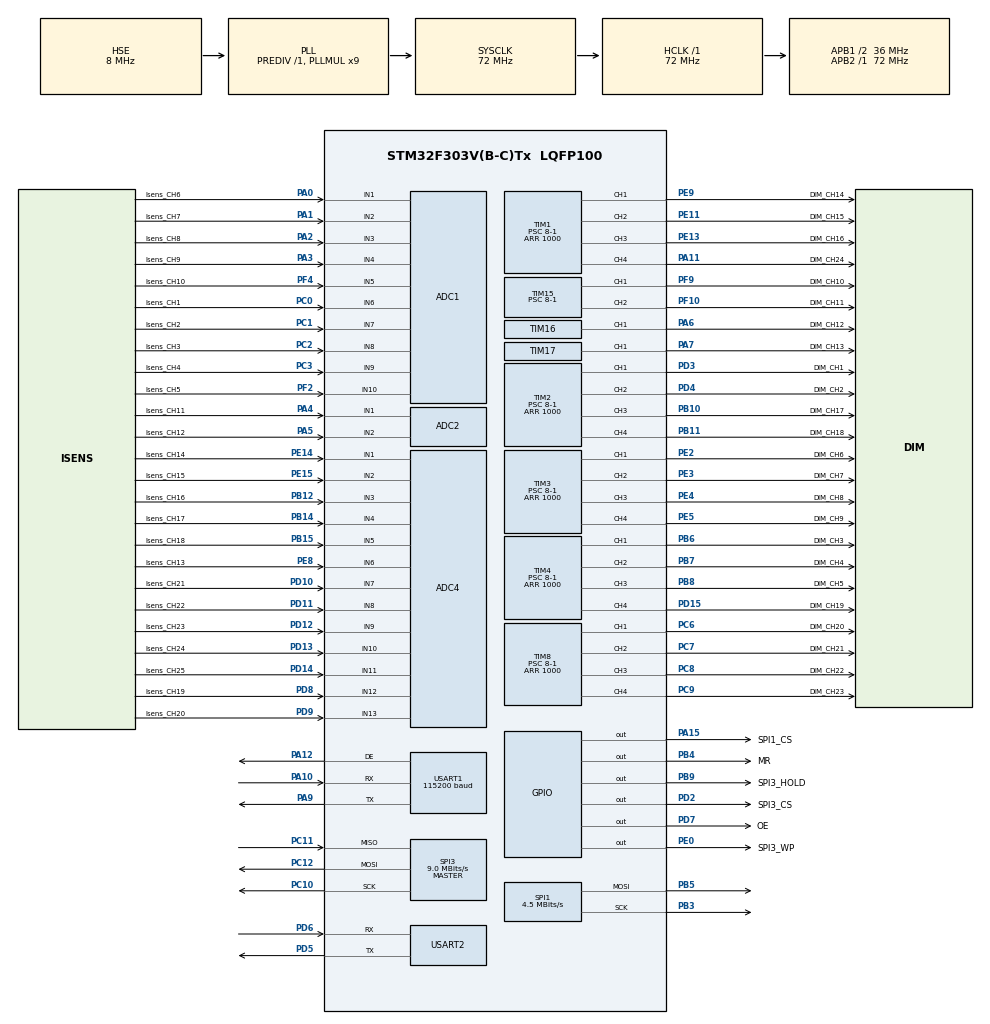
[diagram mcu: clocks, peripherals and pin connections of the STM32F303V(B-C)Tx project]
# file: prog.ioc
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ADC1.Channel-0\#ChannelRegularConversion=ADC_CHANNEL_6
ADC1.Channel-1\#ChannelRegularConversion=ADC_CHANNEL_7
ADC1.Channel-2\#ChannelRegularConversion=ADC_CHANNEL_8
ADC1.Channel-3\#ChannelRegularConversion=ADC_CHANNEL_9
ADC1.Channel-4\#ChannelRegularConversion=ADC_CHANNEL_10
ADC1.Channel-5\#ChannelRegularConversion=ADC_CHANNEL_1
ADC1.Channel-6\#ChannelRegularConversion=ADC_CHANNEL_2
ADC1.Channel-7\#ChannelRegularConversion=ADC_CHANNEL_3
ADC1.Channel-8\#ChannelRegularConversion=ADC_CHANNEL_4
ADC1.Channel-9\#ChannelRegularConversion=ADC_CHANNEL_5
ADC1.ClockPrescaler=ADC_CLOCK_ASYNC_DIV1
ADC1.ContinuousConvMode=ENABLE
ADC1.DMAContinuousRequests=ENABLE
ADC1.EOCSelection=ADC_EOC_SEQ_CONV
ADC1.NbrOfConversion=10
ADC1.NbrOfConversionFlag=1
ADC1.Offset-0\#ChannelRegularConversion=0
ADC1.Offset-1\#ChannelRegularConversion=0
ADC1.Offset-2\#ChannelRegularConversion=0
ADC1.Offset-3\#ChannelRegularConversion=0
ADC1.Offset-4\#ChannelRegularConversion=0
ADC1.Offset-5\#ChannelRegularConversion=0
ADC1.Offset-6\#ChannelRegularConversion=0
ADC1.Offset-7\#ChannelRegularConversion=0
ADC1.Offset-8\#ChannelRegularConversion=0
ADC1.Offset-9\#ChannelRegularConversion=0
ADC1.OffsetNumber-0\#ChannelRegularConversion=ADC_OFFSET_NONE
ADC1.OffsetNumber-1\#ChannelRegularConversion=ADC_OFFSET_NONE
ADC1.OffsetNumber-2\#ChannelRegularConversion=ADC_OFFSET_NONE
ADC1.OffsetNumber-3\#ChannelRegularConversion=ADC_OFFSET_NONE
ADC1.OffsetNumber-4\#ChannelRegularConversion=ADC_OFFSET_NONE
ADC1.OffsetNumber-5\#ChannelRegularConversion=ADC_OFFSET_NONE
ADC1.OffsetNumber-6\#ChannelRegularConversion=ADC_OFFSET_NONE
ADC1.OffsetNumber-7\#ChannelRegularConversion=ADC_OFFSET_NONE
ADC1.OffsetNumber-8\#ChannelRegularConversion=ADC_OFFSET_NONE
ADC1.OffsetNumber-9\#ChannelRegularConversion=ADC_OFFSET_NONE
ADC1.Rank-0\#ChannelRegularConversion=1
ADC1.Rank-1\#ChannelRegularConversion=2
ADC1.Rank-2\#ChannelRegularConversion=3
ADC1.Rank-3\#ChannelRegularConversion=4
ADC1.Rank-4\#ChannelRegularConversion=5
ADC1.Rank-5\#ChannelRegularConversion=6
ADC1.Rank-6\#ChannelRegularConversion=7
ADC1.Rank-7\#ChannelRegularConversion=8
ADC1.Rank-8\#ChannelRegularConversion=9
ADC1.Rank-9\#ChannelRegularConversion=10
ADC1.SamplingTime-0\#ChannelRegularConversion=ADC_SAMPLETIME_601CYCLES_5
ADC1.SamplingTime-1\#ChannelRegularConversion=ADC_SAMPLETIME_601CYCLES_5
ADC1.SamplingTime-2\#ChannelRegularConversion=ADC_SAMPLETIME_601CYCLES_5
ADC1.SamplingTime-3\#ChannelRegularConversion=ADC_SAMPLETIME_601CYCLES_5
ADC1.SamplingTime-4\#ChannelRegularConversion=ADC_SAMPLETIME_601CYCLES_5
ADC1.SamplingTime-5\#ChannelRegularConversion=ADC_SAMPLETIME_601CYCLES_5
ADC1.SamplingTime-6\#ChannelRegularConversion=ADC_SAMPLETIME_601CYCLES_5
ADC1.SamplingTime-7\#ChannelRegularConversion=ADC_SAMPLETIME_601CYCLES_5
ADC1.SamplingTime-8\#ChannelRegularConversion=ADC_SAMPLETIME_601CYCLES_5
ADC1.SamplingTime-9\#ChannelRegularConversion=ADC_SAMPLETIME_601CYCLES_5
ADC1.master=1
ADC2.Channel-2\#ChannelRegularConversion=ADC_CHANNEL_1
ADC2.Channel-3\#ChannelRegularConversion=ADC_CHANNEL_2
ADC2.ContinuousConvMode=ENABLE
ADC2.DMAContinuousRequests=ENABLE
ADC2.EOCSelection=ADC_EOC_SEQ_CONV
ADC2.NbrOfConversion=2
ADC2.NbrOfConversionFlag=1
ADC2.Offset-2\#ChannelRegularConversion=0
ADC2.Offset-3\#ChannelRegularConversion=0
ADC2.OffsetNumber-2\#ChannelRegularConversion=ADC_OFFSET_NONE
ADC2.OffsetNumber-3\#ChannelRegularConversion=ADC_OFFSET_NONE
ADC2.Rank-2\#ChannelRegularConversion=1
ADC2.Rank-3\#ChannelRegularConversion=2
ADC2.SamplingTime-2\#ChannelRegularConversion=ADC_SAMPLETIME_601CYCLES_5
ADC2.SamplingTime-3\#ChannelRegularConversion=ADC_SAMPLETIME_601CYCLES_5
ADC4.Channel-0\#ChannelRegularConversion=ADC_CHANNEL_6
ADC4.Channel-1\#ChannelRegularConversion=ADC_CHANNEL_1
ADC4.Channel-10\#ChannelRegularConversion=ADC_CHANNEL_9
ADC4.Channel-11\#ChannelRegularConversion=ADC_CHANNEL_10
ADC4.Channel-12\#ChannelRegularConversion=ADC_CHANNEL_11
ADC4.Channel-2\#ChannelRegularConversion=ADC_CHANNEL_2
ADC4.Channel-3\#ChannelRegularConversion=ADC_CHANNEL_3
ADC4.Channel-4\#ChannelRegularConversion=ADC_CHANNEL_4
ADC4.Channel-5\#ChannelRegularConversion=ADC_CHANNEL_5
ADC4.Channel-6\#ChannelRegularConversion=ADC_CHANNEL_12
ADC4.Channel-7\#ChannelRegularConversion=ADC_CHANNEL_13
ADC4.Channel-8\#ChannelRegularConversion=ADC_CHANNEL_7
ADC4.Channel-9\#ChannelRegularConversion=ADC_CHANNEL_8
ADC4.ClockPrescaler=ADC_CLOCK_ASYNC_DIV1
ADC4.ContinuousConvMode=ENABLE
ADC4.DMAContinuousRequests=ENABLE
ADC4.EOCSelection=ADC_EOC_SEQ_CONV
ADC4.NbrOfConversion=13
ADC4.NbrOfConversionFlag=1
ADC4.Offset-0\#ChannelRegularConversion=0
ADC4.Offset-1\#ChannelRegularConversion=0
ADC4.Offset-10\#ChannelRegularConversion=0
ADC4.Offset-11\#ChannelRegularConversion=0
ADC4.Offset-12\#ChannelRegularConversion=0
ADC4.Offset-2\#ChannelRegularConversion=0
ADC4.Offset-3\#ChannelRegularConversion=0
ADC4.Offset-4\#ChannelRegularConversion=0
ADC4.Offset-5\#ChannelRegularConversion=0
ADC4.Offset-6\#ChannelRegularConversion=0
ADC4.Offset-7\#ChannelRegularConversion=0
ADC4.Offset-8\#ChannelRegularConversion=0
ADC4.Offset-9\#ChannelRegularConversion=0
ADC4.OffsetNumber-0\#ChannelRegularConversion=ADC_OFFSET_NONE
ADC4.OffsetNumber-1\#ChannelRegularConversion=ADC_OFFSET_NONE
ADC4.OffsetNumber-10\#ChannelRegularConversion=ADC_OFFSET_NONE
ADC4.OffsetNumber-11\#ChannelRegularConversion=ADC_OFFSET_NONE
ADC4.OffsetNumber-12\#ChannelRegularConversion=ADC_OFFSET_NONE
ADC4.OffsetNumber-2\#ChannelRegularConversion=ADC_OFFSET_NONE
ADC4.OffsetNumber-3\#ChannelRegularConversion=ADC_OFFSET_NONE
ADC4.OffsetNumber-4\#ChannelRegularConversion=ADC_OFFSET_NONE
ADC4.OffsetNumber-5\#ChannelRegularConversion=ADC_OFFSET_NONE
ADC4.OffsetNumber-6\#ChannelRegularConversion=ADC_OFFSET_NONE
ADC4.OffsetNumber-7\#ChannelRegularConversion=ADC_OFFSET_NONE
ADC4.OffsetNumber-8\#ChannelRegularConversion=ADC_OFFSET_NONE
ADC4.OffsetNumber-9\#ChannelRegularConversion=ADC_OFFSET_NONE
ADC4.Rank-0\#ChannelRegularConversion=1
ADC4.Rank-1\#ChannelRegularConversion=2
ADC4.Rank-10\#ChannelRegularConversion=11
ADC4.Rank-11\#ChannelRegularConversion=12
ADC4.Rank-12\#ChannelRegularConversion=13
ADC4.Rank-2\#ChannelRegularConversion=3
ADC4.Rank-3\#ChannelRegularConversion=4
ADC4.Rank-4\#ChannelRegularConversion=5
ADC4.Rank-5\#ChannelRegularConversion=6
ADC4.Rank-6\#ChannelRegularConversion=7
ADC4.Rank-7\#ChannelRegularConversion=8
ADC4.Rank-8\#ChannelRegularConversion=9
ADC4.Rank-9\#ChannelRegularConversion=10
ADC4.SamplingTime-0\#ChannelRegularConversion=ADC_SAMPLETIME_601CYCLES_5
ADC4.SamplingTime-1\#ChannelRegularConversion=ADC_SAMPLETIME_601CYCLES_5
ADC4.SamplingTime-10\#ChannelRegularConversion=ADC_SAMPLETIME_601CYCLES_5
ADC4.SamplingTime-11\#ChannelRegularConversion=ADC_SAMPLETIME_601CYCLES_5
ADC4.SamplingTime-12\#ChannelRegularConversion=ADC_SAMPLETIME_601CYCLES_5
ADC4.SamplingTime-2\#ChannelRegularConversion=ADC_SAMPLETIME_601CYCLES_5
ADC4.SamplingTime-3\#ChannelRegularConversion=ADC_SAMPLETIME_601CYCLES_5
ADC4.SamplingTime-4\#ChannelRegularConversion=ADC_SAMPLETIME_601CYCLES_5
ADC4.SamplingTime-5\#ChannelRegularConversion=ADC_SAMPLETIME_601CYCLES_5
ADC4.SamplingTime-6\#ChannelRegularConversion=ADC_SAMPLETIME_601CYCLES_5
ADC4.SamplingTime-7\#ChannelRegularConversion=ADC_SAMPLETIME_601CYCLES_5
ADC4.SamplingTime-8\#ChannelRegularConversion=ADC_SAMPLETIME_601CYCLES_5
ADC4.SamplingTime-9\#ChannelRegularConversion=ADC_SAMPLETIME_601CYCLES_5
Dma.ADC1.0.Direction=DMA_PERIPH_TO_MEMORY
Dma.ADC1.0.Instance=DMA1_Channel1
Dma.ADC1.0.MemDataAlignment=DMA_MDATAALIGN_HALFWORD
Dma.ADC1.0.MemInc=DMA_MINC_ENABLE
Dma.ADC1.0.Mode=DMA_CIRCULAR
Dma.ADC1.0.PeriphDataAlignment=DMA_PDATAALIGN_HALFWORD
Dma.ADC1.0.PeriphInc=DMA_PINC_DISABLE
Dma.ADC1.0.Priority=DMA_PRIORITY_LOW
Dma.ADC2.1.Direction=DMA_PERIPH_TO_MEMORY
Dma.ADC2.1.Instance=DMA2_Channel1
Dma.ADC2.1.MemDataAlignment=DMA_MDATAALIGN_HALFWORD
Dma.ADC2.1.MemInc=DMA_MINC_ENABLE
Dma.ADC2.1.Mode=DMA_CIRCULAR
Dma.ADC2.1.PeriphDataAlignment=DMA_PDATAALIGN_HALFWORD
Dma.ADC2.1.PeriphInc=DMA_PINC_DISABLE
Dma.ADC2.1.Priority=DMA_PRIORITY_LOW
Dma.ADC4.2.Direction=DMA_PERIPH_TO_MEMORY
Dma.ADC4.2.Instance=DMA2_Channel2
Dma.ADC4.2.MemDataAlignment=DMA_MDATAALIGN_HALFWORD
Dma.ADC4.2.MemInc=DMA_MINC_ENABLE
Dma.ADC4.2.Mode=DMA_CIRCULAR
Dma.ADC4.2.PeriphDataAlignment=DMA_PDATAALIGN_HALFWORD
Dma.ADC4.2.PeriphInc=DMA_PINC_DISABLE
Dma.ADC4.2.Priority=DMA_PRIORITY_LOW
Dma.Request0=ADC1
Dma.Request1=ADC2
Dma.Request2=ADC4
FREERTOS.Tasks01=MainTask,0,512,StartDefaultTask,Default,NULL,Dynamic,NULL,NULL;ModBus_Task,0,512,ModBusTask,Default,NULL,Dynamic,NULL,NULL
FREERTOS.configTOTAL_HEAP_SIZE=20480
Mcu.Family=STM32F3
Mcu.Name=STM32F303V(B-C)Tx
Mcu.Package=LQFP100
NVIC.DMA1_Channel1_IRQn=true\:5\:0\:false\:false\:true\:true\:false\:true
NVIC.DMA2_Channel1_IRQn=true\:5\:0\:false\:false\:true\:true\:false\:true
NVIC.DMA2_Channel2_IRQn=true\:5\:0\:false\:false\:true\:true\:false\:true
NVIC.PriorityGroup=NVIC_PRIORITYGROUP_4
NVIC.TIM6_DAC_IRQn=true\:5\:0\:false\:false\:true\:true\:true\:true
NVIC.TIM7_IRQn=true\:0\:0\:false\:false\:true\:false\:false\:true
NVIC.TimeBase=TIM7_IRQn
NVIC.TimeBaseIP=TIM7
NVIC.USART1_IRQn=true\:5\:0\:false\:false\:true\:true\:true\:true
PA0.GPIO_Label=Isens_CH6
PA0.Mode=IN1-Single-Ended
PA0.Signal=ADC1_IN1
PA1.GPIO_Label=Isens_CH7
PA1.Mode=IN2-Single-Ended
PA1.Signal=ADC1_IN2
PA10.Mode=Asynchronous
PA10.Signal=USART1_RX
PA11.GPIO_Label=DIM_CH24
PA11.GPIO_Speed=GPIO_SPEED_FREQ_HIGH
PA11.Signal=S_TIM1_CH4
PA12.Mode=Hardware Flow Control (RS485)
PA12.Signal=USART1_DE
PA13.Mode=Serial_Wire
PA13.Signal=SYS_JTMS-SWDIO
PA14.Mode=Serial_Wire
PA14.Signal=SYS_JTCK-SWCLK
PA15.GPIO_Label=SPI1_CS
PA15.Signal=GPIO_Output
PA2.GPIO_Label=Isens_CH8
PA2.Mode=IN3-Single-Ended
PA2.Signal=ADC1_IN3
PA3.GPIO_Label=Isens_CH9
PA3.Mode=IN4-Single-Ended
PA3.Signal=ADC1_IN4
PA4.GPIO_Label=Isens_CH11
PA4.Mode=IN1-Single-Ended
PA4.Signal=ADC2_IN1
PA5.GPIO_Label=Isens_CH12
PA5.Mode=IN2-Single-Ended
PA5.Signal=ADC2_IN2
PA6.GPIO_Label=DIM_CH12
PA6.GPIO_Speed=GPIO_SPEED_FREQ_HIGH
PA6.Signal=S_TIM16_CH1
PA7.GPIO_Label=DIM_CH13
PA7.GPIO_Speed=GPIO_SPEED_FREQ_HIGH
PA7.Signal=S_TIM17_CH1
PA9.Mode=Asynchronous
PA9.Signal=USART1_TX
PB10.GPIO_Label=DIM_CH17
PB10.GPIO_Speed=GPIO_SPEED_FREQ_HIGH
PB10.Signal=S_TIM2_CH3
PB11.GPIO_Label=DIM_CH18
PB11.GPIO_Speed=GPIO_SPEED_FREQ_HIGH
PB11.Signal=S_TIM2_CH4
PB12.GPIO_Label=Isens_CH16
PB12.Mode=IN3-Single-Ended
PB12.Signal=ADC4_IN3
PB14.GPIO_Label=Isens_CH17
PB14.Mode=IN4-Single-Ended
PB14.Signal=ADC4_IN4
PB15.GPIO_Label=Isens_CH18
PB15.Mode=IN5-Single-Ended
PB15.Signal=ADC4_IN5
PB3.Mode=TX_Only_Simplex_Unidirect_Master
PB3.Signal=SPI1_SCK
PB4.GPIO_Label=MR
PB4.Signal=GPIO_Output
PB5.Mode=TX_Only_Simplex_Unidirect_Master
PB5.Signal=SPI1_MOSI
PB6.GPIO_Label=DIM_CH3
PB6.GPIO_Speed=GPIO_SPEED_FREQ_HIGH
PB6.Signal=S_TIM4_CH1
PB7.GPIO_Label=DIM_CH4
PB7.GPIO_Speed=GPIO_SPEED_FREQ_HIGH
PB7.Signal=S_TIM4_CH2
PB8.GPIO_Label=DIM_CH5
PB8.GPIO_Speed=GPIO_SPEED_FREQ_HIGH
PB8.Signal=S_TIM4_CH3
PB9.GPIO_Label=SPI3_HOLD
PB9.Signal=GPIO_Output
PC0.GPIO_Label=Isens_CH1
PC0.Signal=ADCx_IN6
PC1.GPIO_Label=Isens_CH2
PC1.Signal=ADCx_IN7
PC10.Mode=Full_Duplex_Master
PC10.Signal=SPI3_SCK
PC11.Mode=Full_Duplex_Master
PC11.Signal=SPI3_MISO
PC12.Mode=Full_Duplex_Master
PC12.Signal=SPI3_MOSI
PC2.GPIO_Label=Isens_CH3
PC2.Signal=ADCx_IN8
PC3.GPIO_Label=Isens_CH4
PC3.Signal=ADCx_IN9
PC6.GPIO_Label=DIM_CH20
PC6.GPIO_Speed=GPIO_SPEED_FREQ_HIGH
PC6.Signal=S_TIM8_CH1
PC7.GPIO_Label=DIM_CH21
PC7.GPIO_Speed=GPIO_SPEED_FREQ_HIGH
PC7.Signal=S_TIM8_CH2
PC8.GPIO_Label=DIM_CH22
PC8.GPIO_Speed=GPIO_SPEED_FREQ_HIGH
PC8.Signal=S_TIM8_CH3
PC9.GPIO_Label=DIM_CH23
PC9.GPIO_Speed=GPIO_SPEED_FREQ_HIGH
PC9.Signal=S_TIM8_CH4
PD10.GPIO_Label=Isens_CH21
PD10.Signal=ADCx_IN7P
PD11.GPIO_Label=Isens_CH22
PD11.Signal=ADCx_IN8P
PD12.GPIO_Label=Isens_CH23
PD12.Signal=ADCx_IN9P
PD13.GPIO_Label=Isens_CH24
PD13.Signal=ADCx_IN10P
PD14.GPIO_Label=Isens_CH25
PD14.Signal=ADCx_IN11
PD15.GPIO_Label=DIM_CH19
PD15.GPIO_Speed=GPIO_SPEED_FREQ_HIGH
PD15.Signal=S_TIM4_CH4
PD2.GPIO_Label=SPI3_CS
PD2.Signal=GPIO_Output
PD3.GPIO_Label=DIM_CH1
PD3.GPIO_Speed=GPIO_SPEED_FREQ_HIGH
PD3.Signal=S_TIM2_CH1_ETR
PD4.GPIO_Label=DIM_CH2
PD4.GPIO_Speed=GPIO_SPEED_FREQ_HIGH
PD4.Signal=S_TIM2_CH2
PD5.Mode=Asynchronous
PD5.Signal=USART2_TX
PD6.Mode=Asynchronous
PD6.Signal=USART2_RX
PD7.GPIO_Label=OE
PD7.Signal=GPIO_Output
PD8.GPIO_Label=Isens_CH19
PD8.Mode=IN12-Single-Ended
PD8.Signal=ADC4_IN12
PD9.GPIO_Label=Isens_CH20
PD9.Mode=IN13-Single-Ended
PD9.Signal=ADC4_IN13
PE0.GPIO_Label=SPI3_WP
PE0.Signal=GPIO_Output
PE11.GPIO_Label=DIM_CH15
PE11.GPIO_Speed=GPIO_SPEED_FREQ_HIGH
PE11.Signal=S_TIM1_CH2
PE13.GPIO_Label=DIM_CH16
PE13.GPIO_Speed=GPIO_SPEED_FREQ_HIGH
PE13.Signal=S_TIM1_CH3
PE14.GPIO_Label=Isens_CH14
PE14.Mode=IN1-Single-Ended
PE14.Signal=ADC4_IN1
PE15.GPIO_Label=Isens_CH15
PE15.Mode=IN2-Single-Ended
PE15.Signal=ADC4_IN2
PE2.GPIO_Label=DIM_CH6
PE2.GPIO_Speed=GPIO_SPEED_FREQ_HIGH
PE2.Signal=S_TIM3_CH1
PE3.GPIO_Label=DIM_CH7
PE3.GPIO_Speed=GPIO_SPEED_FREQ_HIGH
PE3.Signal=S_TIM3_CH2
PE4.GPIO_Label=DIM_CH8
PE4.GPIO_Speed=GPIO_SPEED_FREQ_HIGH
PE4.Signal=S_TIM3_CH3
PE5.GPIO_Label=DIM_CH9
PE5.GPIO_Speed=GPIO_SPEED_FREQ_HIGH
PE5.Signal=S_TIM3_CH4
PE8.GPIO_Label=Isens_CH13
PE8.Signal=ADCx_IN6P
PE9.GPIO_Label=DIM_CH14
PE9.GPIO_Speed=GPIO_SPEED_FREQ_HIGH
PE9.Signal=S_TIM1_CH1
PF0-OSC_IN.Mode=HSE-External-Oscillator
PF0-OSC_IN.Signal=RCC_OSC_IN
PF1-OSC_OUT.Mode=HSE-External-Oscillator
PF1-OSC_OUT.Signal=RCC_OSC_OUT
PF10.GPIO_Label=DIM_CH11
PF10.GPIO_Speed=GPIO_SPEED_FREQ_HIGH
PF10.Signal=S_TIM15_CH2
PF2.GPIO_Label=Isens_CH5
PF2.Signal=ADCx_IN10
PF4.GPIO_Label=Isens_CH10
PF4.Mode=IN5-Single-Ended
PF4.Signal=ADC1_IN5
PF9.GPIO_Label=DIM_CH10
PF9.GPIO_Speed=GPIO_SPEED_FREQ_HIGH
PF9.Signal=S_TIM15_CH1
ProjectManager.HeapSize=0x400
ProjectManager.StackSize=0x800
ProjectManager.TargetToolchain=EWARM V8.32
RCC.ADC12PRES=RCC_ADC12PLLCLK_DIV6
RCC.ADC34PRES=RCC_ADC34PLLCLK_DIV6
RCC.AHBFreq_Value=72000000
RCC.APB1CLKDivider=RCC_HCLK_DIV2
RCC.APB1Freq_Value=36000000
RCC.APB1TimFreq_Value=72000000
RCC.APB2Freq_Value=72000000
RCC.APB2TimFreq_Value=72000000
RCC.CortexFreq_Value=72000000
RCC.HCLKFreq_Value=72000000
RCC.HSE_VALUE=8000000
RCC.HSI_VALUE=8000000
RCC.LSE_VALUE=32768
RCC.PLLMUL=RCC_PLL_MUL9
RCC.PLLSourceVirtual=RCC_PLLSOURCE_HSE
RCC.SYSCLKFreq_VALUE=72000000
RCC.SYSCLKSourceVirtual=RCC_SYSCLKSOURCE_PLLCLK
RCC.USBFreq_Value=72000000
SH.ADCx_IN10.0=ADC1_IN10,IN10-Single-Ended
SH.ADCx_IN10P.0=ADC4_IN10,IN10-Single-Ended
SH.ADCx_IN11.0=ADC4_IN11,IN11-Single-Ended
SH.ADCx_IN6.0=ADC1_IN6,IN6-Single-Ended
SH.ADCx_IN6P.0=ADC4_IN6,IN6-Single-Ended
SH.ADCx_IN7.0=ADC1_IN7,IN7-Single-Ended
SH.ADCx_IN7P.0=ADC4_IN7,IN7-Single-Ended
SH.ADCx_IN8.0=ADC1_IN8,IN8-Single-Ended
SH.ADCx_IN8P.0=ADC4_IN8,IN8-Single-Ended
SH.ADCx_IN9.0=ADC1_IN9,IN9-Single-Ended
SH.ADCx_IN9P.0=ADC4_IN9,IN9-Single-Ended
SH.S_TIM15_CH1.0=TIM15_CH1,PWM Generation1 CH1
SH.S_TIM15_CH2.0=TIM15_CH2,PWM Generation2 CH2
SH.S_TIM16_CH1.0=TIM16_CH1,PWM Generation1 CH1
SH.S_TIM17_CH1.0=TIM17_CH1,PWM Generation1 CH1
SH.S_TIM1_CH1.0=TIM1_CH1,PWM Generation1 CH1
SH.S_TIM1_CH2.0=TIM1_CH2,PWM Generation2 CH2
SH.S_TIM1_CH3.0=TIM1_CH3,PWM Generation3 CH3
SH.S_TIM1_CH4.0=TIM1_CH4,PWM Generation4 CH4
SH.S_TIM2_CH1_ETR.0=TIM2_CH1,PWM Generation1 CH1
SH.S_TIM2_CH2.0=TIM2_CH2,PWM Generation2 CH2
SH.S_TIM2_CH3.0=TIM2_CH3,PWM Generation3 CH3
SH.S_TIM2_CH4.0=TIM2_CH4,PWM Generation4 CH4
SH.S_TIM3_CH1.0=TIM3_CH1,PWM Generation1 CH1
SH.S_TIM3_CH2.0=TIM3_CH2,PWM Generation2 CH2
SH.S_TIM3_CH3.0=TIM3_CH3,PWM Generation3 CH3
SH.S_TIM3_CH4.0=TIM3_CH4,PWM Generation4 CH4
SH.S_TIM4_CH1.0=TIM4_CH1,PWM Generation1 CH1
SH.S_TIM4_CH2.0=TIM4_CH2,PWM Generation2 CH2
SH.S_TIM4_CH3.0=TIM4_CH3,PWM Generation3 CH3
SH.S_TIM4_CH4.0=TIM4_CH4,PWM Generation4 CH4
SH.S_TIM8_CH1.0=TIM8_CH1,PWM Generation1 CH1
SH.S_TIM8_CH2.0=TIM8_CH2,PWM Generation2 CH2
SH.S_TIM8_CH3.0=TIM8_CH3,PWM Generation3 CH3
SH.S_TIM8_CH4.0=TIM8_CH4,PWM Generation4 CH4
SPI1.BaudRatePrescaler=SPI_BAUDRATEPRESCALER_16
SPI1.CLKPolarity=SPI_POLARITY_LOW
SPI1.CalculateBaudRate=4.5 MBits/s
SPI1.DataSize=SPI_DATASIZE_8BIT
SPI1.Direction=SPI_DIRECTION_2LINES
SPI1.FirstBit=SPI_FIRSTBIT_LSB
SPI1.Mode=SPI_MODE_MASTER
SPI1.VirtualType=VM_MASTER
SPI3.BaudRatePrescaler=SPI_BAUDRATEPRESCALER_4
SPI3.CalculateBaudRate=9.0 MBits/s
SPI3.DataSize=SPI_DATASIZE_8BIT
SPI3.Direction=SPI_DIRECTION_2LINES
SPI3.Mode=SPI_MODE_MASTER
SPI3.VirtualType=VM_MASTER
TIM1.Channel-PWM\ Generation1\ CH1=TIM_CHANNEL_1
TIM1.Channel-PWM\ Generation2\ CH2=TIM_CHANNEL_2
TIM1.Channel-PWM\ Generation3\ CH3=TIM_CHANNEL_3
TIM1.Channel-PWM\ Generation4\ CH4=TIM_CHANNEL_4
TIM1.Period=1000
TIM1.Prescaler=8-1
TIM15.Channel-PWM\ Generation1\ CH1=TIM_CHANNEL_1
TIM15.Channel-PWM\ Generation2\ CH2=TIM_CHANNEL_2
TIM15.Period=1000
TIM15.Prescaler=8-1
TIM16.Channel=TIM_CHANNEL_1
TIM16.Period=1000
TIM16.Prescaler=8-1
TIM17.Channel=TIM_CHANNEL_1
TIM17.Period=1000
TIM17.Prescaler=8-1
TIM2.Channel-PWM\ Generation1\ CH1=TIM_CHANNEL_1
TIM2.Channel-PWM\ Generation2\ CH2=TIM_CHANNEL_2
TIM2.Channel-PWM\ Generation3\ CH3=TIM_CHANNEL_3
TIM2.Channel-PWM\ Generation4\ CH4=TIM_CHANNEL_4
TIM2.Period=1000
TIM2.Prescaler=8-1
TIM3.Channel-PWM\ Generation1\ CH1=TIM_CHANNEL_1
TIM3.Channel-PWM\ Generation2\ CH2=TIM_CHANNEL_2
TIM3.Channel-PWM\ Generation3\ CH3=TIM_CHANNEL_3
TIM3.Channel-PWM\ Generation4\ CH4=TIM_CHANNEL_4
TIM3.Period=1000
TIM3.Prescaler=8-1
TIM4.Channel-PWM\ Generation1\ CH1=TIM_CHANNEL_1
TIM4.Channel-PWM\ Generation2\ CH2=TIM_CHANNEL_2
TIM4.Channel-PWM\ Generation3\ CH3=TIM_CHANNEL_3
TIM4.Channel-PWM\ Generation4\ CH4=TIM_CHANNEL_4
TIM4.Period=1000
TIM4.Prescaler=8-1
TIM8.Channel-PWM\ Generation1\ CH1=TIM_CHANNEL_1
TIM8.Channel-PWM\ Generation2\ CH2=TIM_CHANNEL_2
TIM8.Channel-PWM\ Generation3\ CH3=TIM_CHANNEL_3
TIM8.Channel-PWM\ Generation4\ CH4=TIM_CHANNEL_4
TIM8.Period=1000
TIM8.Prescaler=8-1
USART1.BaudRate=115200
USART1.VirtualMode-Asynchronous=VM_ASYNC
USART1.VirtualMode-Hardware\ Flow\ Control\ (RS485)=VM_ASYNC
USART2.VirtualMode-Asynchronous=VM_ASYNC
VP_FREERTOS_VS_CMSIS_V1.Mode=CMSIS_V1
VP_SYS_VS_tim7.Mode=TIM7
VP_TIM16_VS_ClockSourceINT.Mode=Enable_Timer
VP_TIM17_VS_ClockSourceINT.Mode=Enable_Timer
VP_TIM6_VS_ClockSourceINT.Mode=Enable_Timer
board=custom

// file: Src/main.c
/* USER CODE BEGIN Header */
/**
  ******************************************************************************
  * @file           : main.c
  * @brief          : Main program body
  ******************************************************************************
  * @attention
  *
  * <h2><center>&copy; Copyright (c) 2020 STMicroelectronics.
  * All rights reserved.</center></h2>
  *
  * This software component is licensed by ST under BSD 3-Clause license,
  * the "License"; You may not use this file except in compliance with the
  * License. You may obtain a copy of the License at:
  *                        opensource.org/licenses/BSD-3-Clause
  *
  ******************************************************************************
  */
/* USER CODE END Header */
#include "main.h"
#include "cmsis_os.h"
#include "adc.h"
#include "dma.h"
#include "spi.h"
#include "tim.h"
#include "usart.h"
#include "gpio.h"

/* USER CODE BEGIN Includes */
#include "flash_spi.h"
/* USER CODE END Includes */

/* USER CODE BEGIN PV */
settings_t settings = {0,}; //{115200, 0x0D, 0};
bool resetSettings = false;
flash *FlashP;
/* USER CODE END PV */

void SystemClock_Config(void);
void MX_FREERTOS_Init(void);

int main(void)
{

  /* MCU Configuration--------------------------------------------------------*/

  /* Reset of all peripherals, Initializes the Flash interface and the Systick. */
  HAL_Init();

  /* Configure the system clock */
  SystemClock_Config();

  /* Initialize all configured peripherals */
  MX_GPIO_Init();
  MX_ADC1_Init();
  MX_ADC4_Init();
  MX_TIM1_Init();
  MX_TIM2_Init();
  MX_TIM3_Init();
  MX_TIM4_Init();
  MX_TIM8_Init();
  MX_TIM6_Init();
  MX_USART1_UART_Init();
  MX_ADC2_Init();
  MX_SPI1_Init();
  MX_SPI3_Init();
  MX_TIM15_Init();
  MX_TIM16_Init();
  MX_TIM17_Init();
  MX_DMA_Init();
  MX_USART2_UART_Init();
  /* USER CODE BEGIN 2 */
  flash Flash;
//  pins_spi_t cs = {SPI3_CS_GPIO_Port, SPI3_CS_Pin};
//  pins_spi_t wp = {SPI3_WP_GPIO_Port, SPI3_WP_Pin};
//  pins_spi_t hold = {SPI3_HOLD_GPIO_Port, SPI3_HOLD_Pin};

  FlashP = &Flash;
  FlashP->Init(&hspi3, 1, {SPI3_CS_GPIO_Port, SPI3_CS_Pin}, {SPI3_WP_GPIO_Port, SPI3_WP_Pin}, {SPI3_HOLD_GPIO_Port, SPI3_HOLD_Pin});

  FlashP->Read(&settings);

  if((settings.BaudRate == 0) | (settings.BaudRate == 0xFFFFFFFF) | resetSettings)
    {

      settings.BaudRate = 115200;
      settings.SlaveAddress = 0x0D;
      FlashP->Write(settings);
    }

      HAL_TIM_PWM_Start(&htim2, TIM_CHANNEL_1); //CH1
      HAL_TIM_PWM_Start(&htim2, TIM_CHANNEL_2); //CH2
      HAL_TIM_PWM_Start(&htim4, TIM_CHANNEL_1); //CH3
      HAL_TIM_PWM_Start(&htim4, TIM_CHANNEL_4); //CH4
      HAL_TIM_PWM_Start(&htim4, TIM_CHANNEL_3); //CH5

      HAL_TIM_PWM_Start(&htim3, TIM_CHANNEL_1); //CH6
      HAL_TIM_PWM_Start(&htim3, TIM_CHANNEL_2); //CH7
      HAL_TIM_PWM_Start(&htim3, TIM_CHANNEL_3); //CH8
      HAL_TIM_PWM_Start(&htim3, TIM_CHANNEL_4); //CH9
      HAL_TIM_PWM_Start(&htim15, TIM_CHANNEL_1); //CH10

      HAL_TIM_PWM_Start(&htim15, TIM_CHANNEL_2); //CH11
      HAL_TIM_PWM_Start(&htim16, TIM_CHANNEL_1); //CH12
      HAL_TIM_PWM_Start(&htim17, TIM_CHANNEL_1); //CH13
      HAL_TIM_PWM_Start(&htim1, TIM_CHANNEL_1); //CH14
      HAL_TIM_PWM_Start(&htim1, TIM_CHANNEL_2); //CH15

      HAL_TIM_PWM_Start(&htim1, TIM_CHANNEL_3); //CH16
      HAL_TIM_PWM_Start(&htim2, TIM_CHANNEL_3); //CH17
      HAL_TIM_PWM_Start(&htim2, TIM_CHANNEL_4); //CH18
      HAL_TIM_PWM_Start(&htim4, TIM_CHANNEL_4); //CH19
      HAL_TIM_PWM_Start(&htim8, TIM_CHANNEL_1); //CH20

      HAL_TIM_PWM_Start(&htim8, TIM_CHANNEL_2); //CH21
      HAL_TIM_PWM_Start(&htim8, TIM_CHANNEL_3); //CH22
      HAL_TIM_PWM_Start(&htim8, TIM_CHANNEL_4); //CH23
      HAL_TIM_PWM_Start(&htim1, TIM_CHANNEL_4); //CH24, CH25
      //HAL_TIM_PWM_Start(&htim2, TIM_CHANNEL_1); //CH25

  /* USER CODE END 2 */

  /* Call init function for freertos objects (in freertos.c) */
  MX_FREERTOS_Init();
  /* Start scheduler */
  osKernelStart();

  /* We should never get here as control is now taken by the scheduler */
  /* Infinite loop */
  while (1)
  {

  }
}

void SystemClock_Config(void)
{
  RCC_OscInitTypeDef RCC_OscInitStruct = {0};
  RCC_ClkInitTypeDef RCC_ClkInitStruct = {0};
  RCC_PeriphCLKInitTypeDef PeriphClkInit = {0};

  /** Initializes the RCC Oscillators according to the specified parameters
  * in the RCC_OscInitTypeDef structure.
  */
  RCC_OscInitStruct.OscillatorType = RCC_OSCILLATORTYPE_HSE;
  RCC_OscInitStruct.HSEState = RCC_HSE_ON;
  RCC_OscInitStruct.HSEPredivValue = RCC_HSE_PREDIV_DIV1;
  RCC_OscInitStruct.HSIState = RCC_HSI_ON;
  RCC_OscInitStruct.PLL.PLLState = RCC_PLL_ON;
  RCC_OscInitStruct.PLL.PLLSource = RCC_PLLSOURCE_HSE;
  RCC_OscInitStruct.PLL.PLLMUL = RCC_PLL_MUL9;
  if (HAL_RCC_OscConfig(&RCC_OscInitStruct) != HAL_OK)
  {
    Error_Handler();
  }
  /** Initializes the CPU, AHB and APB buses clocks
  */
  RCC_ClkInitStruct.ClockType = RCC_CLOCKTYPE_HCLK|RCC_CLOCKTYPE_SYSCLK
                              |RCC_CLOCKTYPE_PCLK1|RCC_CLOCKTYPE_PCLK2;
  RCC_ClkInitStruct.SYSCLKSource = RCC_SYSCLKSOURCE_PLLCLK;
  RCC_ClkInitStruct.AHBCLKDivider = RCC_SYSCLK_DIV1;
  RCC_ClkInitStruct.APB1CLKDivider = RCC_HCLK_DIV2;
  RCC_ClkInitStruct.APB2CLKDivider = RCC_HCLK_DIV1;

  if (HAL_RCC_ClockConfig(&RCC_ClkInitStruct, FLASH_LATENCY_2) != HAL_OK)
  {
    Error_Handler();
  }
  PeriphClkInit.PeriphClockSelection = RCC_PERIPHCLK_USART1|RCC_PERIPHCLK_USART2
                              |RCC_PERIPHCLK_TIM1|RCC_PERIPHCLK_TIM8
                              |RCC_PERIPHCLK_ADC12|RCC_PERIPHCLK_ADC34;
  PeriphClkInit.Usart1ClockSelection = RCC_USART1CLKSOURCE_PCLK2;
  PeriphClkInit.Usart2ClockSelection = RCC_USART2CLKSOURCE_PCLK1;
  PeriphClkInit.Adc12ClockSelection = RCC_ADC12PLLCLK_DIV6;
  PeriphClkInit.Adc34ClockSelection = RCC_ADC34PLLCLK_DIV6;
  PeriphClkInit.Tim1ClockSelection = RCC_TIM1CLK_HCLK;
  PeriphClkInit.Tim8ClockSelection = RCC_TIM8CLK_HCLK;
  if (HAL_RCCEx_PeriphCLKConfig(&PeriphClkInit) != HAL_OK)
  {
    Error_Handler();
  }
}

/* USER CODE BEGIN 4 */
double map(double x, double in_min, double in_max, double out_min, double out_max)
{
  return (x - in_min) * (out_max - out_min) / (in_max - in_min) + out_min;
}
/* USER CODE END 4 */

void HAL_TIM_PeriodElapsedCallback(TIM_HandleTypeDef *htim)
{
  if (htim->Instance == TIM7) {
    HAL_IncTick();
  }
}

void Error_Handler(void)
{
}

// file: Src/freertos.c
/* USER CODE BEGIN Header */
/**
******************************************************************************
* File Name          : freertos.c
* Description        : Code for freertos applications
******************************************************************************
* @attention
*
* <h2><center>&copy; Copyright (c) 2020 STMicroelectronics.
* All rights reserved.</center></h2>
*
* This software component is licensed by ST under Ultimate Liberty license
* SLA0044, the "License"; You may not use this file except in compliance with
* the License. You may obtain a copy of the License at:
*                             www.st.com/SLA0044
*
******************************************************************************
*/
/* USER CODE END Header */

#include "FreeRTOS.h"
#include "task.h"
#include "main.h"
#include "cmsis_os.h"

/* USER CODE BEGIN Includes */
#include "mb.h"
#include "mbport.h"
#include "flash_spi.h"

using namespace std;

#define start_addr               10
#define addr_dim_chanels        sart_addr
#define addr_enable_chanels     addr_dim_chanels + 25
#define end_w_and_start_r       addr_enable_chanels + 25
#define addr_chanels_is_down    end_w_and_start_r
#define end_r                   addr_chanels_is_down + 25
/* USER CODE END Includes */

/* USER CODE BEGIN PD */
#define CH1 TIM2->CCR1 //CH1
#define CH2 TIM2->CCR2 //CH2
#define CH3 TIM4->CCR1 //CH3
#define CH4 TIM4->CCR4 //CH4
#define CH5 TIM4->CCR3 //CH5

#define CH6 TIM3->CCR1 //CH6
#define CH7 TIM3->CCR2 //CH7
#define CH8 TIM3->CCR3 //CH8
#define CH9 TIM3->CCR4 //CH9
#define CH10 TIM15->CCR1 //CH10

#define CH11 TIM15->CCR2 //CH11
#define CH12 TIM16->CCR1 //CH12
#define CH13 TIM17->CCR1 //CH13
#define CH14 TIM1->CCR1 //CH14
#define CH15 TIM1->CCR2 //CH15

#define CH16 TIM1->CCR3 //CH16
#define CH17 TIM2->CCR3 //CH17
#define CH18 TIM2->CCR4 //CH18
#define CH19 TIM4->CCR4 //CH19
#define CH20 TIM8->CCR1 //CH20

#define CH21 TIM8->CCR2 //CH21
#define CH22 TIM8->CCR3 //CH22
#define CH23 TIM8->CCR4 //CH23
#define CH24 TIM1->CCR4 //CH24

/* USER CODE END PD */

/* USER CODE BEGIN Variables */
extern ADC_HandleTypeDef hadc1;
extern ADC_HandleTypeDef hadc2;
extern ADC_HandleTypeDef hadc4;
extern SPI_HandleTypeDef hspi1;
extern SPI_HandleTypeDef hspi3;
extern settings_t settings;
extern flash *FlashP;
int start = 1;

uint16_t dim_chanels[25] = {0,};
uint16_t enable_chanels[25] = {0,};
uint16_t chanels_is_down[25] = {0,};
//bufers for adc
uint16_t CH1_CH10[10] = {0,};
uint16_t CH11_CH12[2] = {0,};
uint16_t CH13_CH25[13] = {0,};

uint32_t data_for_hc595 = 0xffffffff;
/* USER CODE END Variables */
osThreadId MainTaskHandle;
osThreadId ModBus_TaskHandle;

/* USER CODE BEGIN FunctionPrototypes */
//   extern "C"
/* USER CODE END FunctionPrototypes */

void StartDefaultTask(void const * argument);
void ModBusTask(void const * argument);

void MX_FREERTOS_Init(void); /* (MISRA C 2004 rule 8.1) */

/* GetIdleTaskMemory prototype (linked to static allocation support) */
extern "C" void vApplicationGetIdleTaskMemory( StaticTask_t **ppxIdleTaskTCBBuffer, StackType_t **ppxIdleTaskStackBuffer, uint32_t *pulIdleTaskStackSize );

/* USER CODE BEGIN GET_IDLE_TASK_MEMORY */
static StaticTask_t xIdleTaskTCBBuffer;
static StackType_t xIdleStack[configMINIMAL_STACK_SIZE];

void vApplicationGetIdleTaskMemory( StaticTask_t **ppxIdleTaskTCBBuffer, StackType_t **ppxIdleTaskStackBuffer, uint32_t *pulIdleTaskStackSize )
{
   *ppxIdleTaskTCBBuffer = &xIdleTaskTCBBuffer;
   *ppxIdleTaskStackBuffer = &xIdleStack[0];
   *pulIdleTaskStackSize = configMINIMAL_STACK_SIZE;
   /* place for user code */
}
/* USER CODE END GET_IDLE_TASK_MEMORY */

void MX_FREERTOS_Init(void) {

  /* Create the thread(s) */
  /* definition and creation of MainTask */
  osThreadDef(MainTask, StartDefaultTask, osPriorityNormal, 0, 512);
  MainTaskHandle = osThreadCreate(osThread(MainTask), NULL);

  /* definition and creation of ModBus_Task */
  osThreadDef(ModBus_Task, ModBusTask, osPriorityNormal, 0, 512);
  ModBus_TaskHandle = osThreadCreate(osThread(ModBus_Task), NULL);

}

void StartDefaultTask(void const * argument)
{
  /* USER CODE BEGIN StartDefaultTask */

   // for hc595
   HAL_StatusTypeDef StatusSPI1;
   HAL_GPIO_WritePin(MR_GPIO_Port, MR_Pin, GPIO_PIN_SET);
   HAL_GPIO_WritePin(OE_GPIO_Port, OE_Pin, GPIO_PIN_RESET);

   CH1 = settings.Channels[0].DIMChannel;
   CH2 = settings.Channels[1].DIMChannel;
   CH3 = settings.Channels[2].DIMChannel;
   CH4 = settings.Channels[3].DIMChannel;
   CH5 = settings.Channels[4].DIMChannel;
   CH6 = settings.Channels[5].DIMChannel;
   CH7 = settings.Channels[6].DIMChannel;
   CH8 = settings.Channels[7].DIMChannel;
   CH9 = settings.Channels[8].DIMChannel;
   CH10 = settings.Channels[9].DIMChannel;
   CH11 = settings.Channels[10].DIMChannel;
   CH12 = settings.Channels[11].DIMChannel;
   CH13 = settings.Channels[12].DIMChannel;
   CH14 = settings.Channels[13].DIMChannel;
   CH15 = settings.Channels[14].DIMChannel;
   CH16 = settings.Channels[15].DIMChannel;
   CH17 = settings.Channels[16].DIMChannel;
   CH18 = settings.Channels[17].DIMChannel;
   CH19 = settings.Channels[18].DIMChannel;
   CH20 = settings.Channels[19].DIMChannel;
   CH21 = settings.Channels[20].DIMChannel;
   CH22 = settings.Channels[21].DIMChannel;
   CH23 = settings.Channels[22].DIMChannel;
   CH24 = settings.Channels[23].DIMChannel;

   // for adc
   HAL_ADC_Start_DMA(&hadc1,(uint32_t*)&CH1_CH10,10);
   HAL_ADC_Start_DMA(&hadc2,(uint32_t*)&CH11_CH12,2);
   HAL_ADC_Start_DMA(&hadc4,(uint32_t*)&CH13_CH25,1);

   /* Infinite loop */
   for(;;)
   {

      HAL_GPIO_WritePin(SPI1_CS_GPIO_Port, SPI1_CS_Pin, GPIO_PIN_RESET);
      StatusSPI1 = HAL_SPI_Transmit(&hspi1, (uint8_t*)&data_for_hc595, 4, 100);
      StatusSPI1 = StatusSPI1;
      HAL_GPIO_WritePin(SPI1_CS_GPIO_Port, SPI1_CS_Pin, GPIO_PIN_SET);

      osDelay(1);
   }

  /* USER CODE END StartDefaultTask */
}

void ModBusTask(void const * argument)
{
  /* USER CODE BEGIN ModBusTask */
   /* Infinite loop */
   eMBErrorCode eStatus = eMBInit( MB_RTU, settings.SlaveAddress, 3, settings.BaudRate, MB_PAR_NONE );
   eStatus = eMBEnable();
   //HAL_TIM_Base_Start_IT(&htim17);
   for(;;)
   {
      eMBPoll();
      //taskYIELD();
   }
  /* USER CODE END ModBusTask */
}

/* USER CODE BEGIN Application */

void HAL_ADC_ConvCpltCallback(ADC_HandleTypeDef* hadc1)
{

}

/*description https://www.freemodbus.org/api/group__modbus__registers.html*/
//0x04
eMBErrorCode
eMBRegInputCB( UCHAR * pucRegBuffer, USHORT usAddress, USHORT usNRegs )
{
   eMBErrorCode    eStatus = MB_ENOERR;

   return eStatus;
}
//0x03 0x06 0x10
eMBErrorCode
eMBRegHoldingCB( UCHAR * pucRegBuffer, USHORT usAddress, USHORT usNRegs, eMBRegisterMode eMode )
{
   eMBErrorCode    eStatus = MB_ENOERR;
   //uint8_t CMD[5] = {0};
   volatile HAL_StatusTypeDef status;

   if(usAddress == 0 ){}
   else{usAddress--;}

   switch (eMode)
   {
     case MB_REG_READ:
      {
         switch (usAddress)
         {
           case 0: //  Stop/Start
            {

               break;
            }
           case 1: // Dir
            {

               break;
            }
           case 2: //Status start/stop
            {

               break;
            }
           case 3: //Status Dir
            {

               break;
            }
           case 4: // RPM
            {

               break;
            }
           case 5: //
            {
               break;
            }
           case 6: //
            {

               break;
            }
           case 7: //
            {
               break;
            }
           case 8:
            {

               break;
            }
           case 9:
            {

               break;
            }
           case 10: // start dim
            {
              uint16_t temp = CH1;
              *(pucRegBuffer) = (temp & 0xff00)>>8;
              *(pucRegBuffer+1) = temp & 0x00ff;
               break;
            }
           case 11:
            {
              uint16_t temp = CH2;
              *(pucRegBuffer) = (temp & 0xff00)>>8;
              *(pucRegBuffer+1) = temp & 0x00ff;
               break;
            }
           case 12:
            {
              uint16_t temp = CH3;
              *(pucRegBuffer) = (temp & 0xff00)>>8;
              *(pucRegBuffer+1) = temp & 0x00ff;
               break;
            }
           case 13:
            {
              uint16_t temp = CH4;
              *(pucRegBuffer) = (temp & 0xff00)>>8;
              *(pucRegBuffer+1) = temp & 0x00ff;
               break;
            }
           case 14:
            {
              uint16_t temp = CH5;
              *(pucRegBuffer) = (temp & 0xff00)>>8;
              *(pucRegBuffer+1) = temp & 0x00ff;
               break;
            }
           case 15:
            {
              uint16_t temp = CH6;
              *(pucRegBuffer) = (temp & 0xff00)>>8;
              *(pucRegBuffer+1) = temp & 0x00ff;
               break;
            }
           case 16:
            {
              uint16_t temp = CH7;
              *(pucRegBuffer) = (temp & 0xff00)>>8;
              *(pucRegBuffer+1) = temp & 0x00ff;
               break;
            }
           case 17:
            {
              uint16_t temp = CH8;
              *(pucRegBuffer) = (temp & 0xff00)>>8;
              *(pucRegBuffer+1) = temp & 0x00ff;
               break;
            }
           case 18:
            {
              uint16_t temp = CH9;
              *(pucRegBuffer) = (temp & 0xff00)>>8;
              *(pucRegBuffer+1) = temp & 0x00ff;
               break;
            }
           case 19:
            {
              uint16_t temp = CH10;
              *(pucRegBuffer) = (temp & 0xff00)>>8;
              *(pucRegBuffer+1) = temp & 0x00ff;
               break;
            }
           case 20:
            {
              uint16_t temp = CH11;
              *(pucRegBuffer) = (temp & 0xff00)>>8;
              *(pucRegBuffer+1) = temp & 0x00ff;
               break;
            }
           case 21:
            {
              uint16_t temp = CH12;
              *(pucRegBuffer) = (temp & 0xff00)>>8;
              *(pucRegBuffer+1) = temp & 0x00ff;
               break;
            }
           case 22:
            {
              uint16_t temp = CH13;
              *(pucRegBuffer) = (temp & 0xff00)>>8;
              *(pucRegBuffer+1) = temp & 0x00ff;
               break;
            }
           case 23:
            {
              uint16_t temp = CH14;
              *(pucRegBuffer) = (temp & 0xff00)>>8;
              *(pucRegBuffer+1) = temp & 0x00ff;
               break;
            }
           case 24:
            {
              uint16_t temp = CH15;
              *(pucRegBuffer) = (temp & 0xff00)>>8;
              *(pucRegBuffer+1) = temp & 0x00ff;
               break;
            }
           case 25:
            {
              uint16_t temp = CH16;
              *(pucRegBuffer) = (temp & 0xff00)>>8;
              *(pucRegBuffer+1) = temp & 0x00ff;
               break;
            }
           case 26:
            {
              uint16_t temp = CH17;
              *(pucRegBuffer) = (temp & 0xff00)>>8;
              *(pucRegBuffer+1) = temp & 0x00ff;
               break;
            }
           case 27:
            {
              uint16_t temp = CH18;
              *(pucRegBuffer) = (temp & 0xff00)>>8;
              *(pucRegBuffer+1) = temp & 0x00ff;
               break;
            }
           case 28:
            {
              uint16_t temp = CH19;
              *(pucRegBuffer) = (temp & 0xff00)>>8;
              *(pucRegBuffer+1) = temp & 0x00ff;
               break;
            }
           case 29:
            {
              uint16_t temp = CH20;
              *(pucRegBuffer) = (temp & 0xff00)>>8;
              *(pucRegBuffer+1) = temp & 0x00ff;
               break;
            }
           case 30:
            {
              uint16_t temp = CH21;
              *(pucRegBuffer) = (temp & 0xff00)>>8;
              *(pucRegBuffer+1) = temp & 0x00ff;
               break;
            }
           case 31:
            {
              uint16_t temp = CH22;
              *(pucRegBuffer) = (temp & 0xff00)>>8;
              *(pucRegBuffer+1) = temp & 0x00ff;
               break;
            }
           case 32:
            {
              uint16_t temp = CH23;
              *(pucRegBuffer) = (temp & 0xff00)>>8;
              *(pucRegBuffer+1) = temp & 0x00ff;
               break;
            }
           case 33:
            {
              uint16_t temp = CH24;
              *(pucRegBuffer) = (temp & 0xff00)>>8;
              *(pucRegBuffer+1) = temp & 0x00ff;
               break;
            }
           case 34: // end dim
            {
              uint16_t temp = CH24;
              *(pucRegBuffer) = (temp & 0xff00)>>8;
              *(pucRegBuffer+1) = temp & 0x00ff;
               break;
            }
           case 35: // start enable
            {
               uint16_t temp = data_for_hc595 & (uint32_t)(1 << 31);
              *(pucRegBuffer) = (temp & 0xff00)>>8;
              *(pucRegBuffer+1) = temp & 0x00ff;

               break;
            }
           case 36:
            {
               uint16_t temp = data_for_hc595 & (uint32_t)(1 << 30);
              *(pucRegBuffer) = (temp & 0xff00)>>8;
              *(pucRegBuffer+1) = temp & 0x00ff;
               break;
            }
           case 37:
            {
               uint16_t temp = data_for_hc595 & (uint32_t)(1 << 29);
              *(pucRegBuffer) = (temp & 0xff00)>>8;
              *(pucRegBuffer+1) = temp & 0x00ff;
               break;
            }
           case 38:
            {
               uint16_t temp = data_for_hc595 & (uint32_t)(1 << 28);
              *(pucRegBuffer) = (temp & 0xff00)>>8;
              *(pucRegBuffer+1) = temp & 0x00ff;
               break;
            }
           case 39:
            {
               uint16_t temp = data_for_hc595 & (uint32_t)(1 << 27);
              *(pucRegBuffer) = (temp & 0xff00)>>8;
              *(pucRegBuffer+1) = temp & 0x00ff;
               break;
            }
           case 40:
            {
               uint16_t temp = data_for_hc595 & (uint32_t)(1 << 26);
              *(pucRegBuffer) = (temp & 0xff00)>>8;
              *(pucRegBuffer+1) = temp & 0x00ff;
               break;
            }
           case 41:
            {
               uint16_t temp = data_for_hc595 & (uint32_t)(1 << 25);
              *(pucRegBuffer) = (temp & 0xff00)>>8;
              *(pucRegBuffer+1) = temp & 0x00ff;
               break;
            }
           case 42:
            {
               uint16_t temp = data_for_hc595 & (uint32_t)(1 << 24);
              *(pucRegBuffer) = (temp & 0xff00)>>8;
              *(pucRegBuffer+1) = temp & 0x00ff;
               break;
            }
           case 43:
            {
               uint16_t temp = data_for_hc595 & (uint32_t)(1 << 23);
              *(pucRegBuffer) = (temp & 0xff00)>>8;
              *(pucRegBuffer+1) = temp & 0x00ff;
               break;
            }
           case 44:
            {
               uint16_t temp = data_for_hc595 & (uint32_t)(1 << 22);
              *(pucRegBuffer) = (temp & 0xff00)>>8;
              *(pucRegBuffer+1) = temp & 0x00ff;
               break;
            }
           case 45:
            {
               uint16_t temp = data_for_hc595 & (uint32_t)(1 << 21);
              *(pucRegBuffer) = (temp & 0xff00)>>8;
              *(pucRegBuffer+1) = temp & 0x00ff;
               break;
            }
           case 46:
            {
               uint16_t temp = data_for_hc595 & (uint32_t)(1 << 20);
              *(pucRegBuffer) = (temp & 0xff00)>>8;
              *(pucRegBuffer+1) = temp & 0x00ff;
               break;
            }
           case 47:
            {
               uint16_t temp = data_for_hc595 & (uint32_t)(1 << 19);
              *(pucRegBuffer) = (temp & 0xff00)>>8;
              *(pucRegBuffer+1) = temp & 0x00ff;
               break;
            }
           case 48:
            {
               uint16_t temp = data_for_hc595 & (uint32_t)(1 << 18);
              *(pucRegBuffer) = (temp & 0xff00)>>8;
              *(pucRegBuffer+1) = temp & 0x00ff;
               break;
            }
           case 49:
            {
               uint16_t temp = data_for_hc595 & (uint32_t)(1 << 17);
              *(pucRegBuffer) = (temp & 0xff00)>>8;
              *(pucRegBuffer+1) = temp & 0x00ff;
               break;
            }
           case 50:
            {
               uint16_t temp = data_for_hc595 & (uint32_t)(1 << 16);
              *(pucRegBuffer) = (temp & 0xff00)>>8;
              *(pucRegBuffer+1) = temp & 0x00ff;
               break;
            }
           case 51:
            {
               uint16_t temp = data_for_hc595 & (uint32_t)(1 << 15);
              *(pucRegBuffer) = (temp & 0xff00)>>8;
              *(pucRegBuffer+1) = temp & 0x00ff;
               break;
            }
           case 52:
            {
               uint16_t temp = data_for_hc595 & (uint32_t)(1 << 14);
              *(pucRegBuffer) = (temp & 0xff00)>>8;
              *(pucRegBuffer+1) = temp & 0x00ff;
               break;
            }
           case 53:
            {
               uint16_t temp = data_for_hc595 & (uint32_t)(1 << 13);
              *(pucRegBuffer) = (temp & 0xff00)>>8;
              *(pucRegBuffer+1) = temp & 0x00ff;
               break;
            }
           case 54:
            {
               uint16_t temp = data_for_hc595 & (uint32_t)(1 << 12);
              *(pucRegBuffer) = (temp & 0xff00)>>8;
              *(pucRegBuffer+1) = temp & 0x00ff;
               break;
            }
           case 55:
            {
               uint16_t temp = data_for_hc595 & (uint32_t)(1 << 11);
              *(pucRegBuffer) = (temp & 0xff00)>>8;
              *(pucRegBuffer+1) = temp & 0x00ff;
               break;
            }
           case 56:
            {
               uint16_t temp = data_for_hc595 & (uint32_t)(1 << 10);
              *(pucRegBuffer) = (temp & 0xff00)>>8;
              *(pucRegBuffer+1) = temp & 0x00ff;
               break;
            }
           case 57:
            {
               uint16_t temp = data_for_hc595 & (uint32_t)(1 << 9);
              *(pucRegBuffer) = (temp & 0xff00)>>8;
              *(pucRegBuffer+1) = temp & 0x00ff;
               break;
            }
           case 58:
            {
               uint16_t temp = data_for_hc595 & (uint32_t)(1 << 8);
              *(pucRegBuffer) = (temp & 0xff00)>>8;
              *(pucRegBuffer+1) = temp & 0x00ff;
               break;
            }
           case 59:
            {
               uint16_t temp = data_for_hc595 & (uint32_t)(1 << 7);
              *(pucRegBuffer) = (temp & 0xff00)>>8;
              *(pucRegBuffer+1) = temp & 0x00ff;
               break;
            }
           case 60: // chanels is down
            {	//V=ADCval*VALmax/ADCmax. 4095

               //*pucRegBuffer = ((UCHAR*) &CH1_CH10[0])+1;
               //*pucRegBuffer +1 = ((UCHAR*) &CH1_CH10[0]);
               break;
            }
           case 61:
            {

               break;
            }
           case 62:
            {

               break;
            }
           case 63:
            {

               break;
            }
           case 64:
            {

               break;
            }
           case 65:
            {

               break;
            }
           case 66:
            {

               break;
            }
           case 67:
            {

               break;
            }
           case 68:
            {

               break;
            }
           case 69:
            {

               break;
            }
           case 70:
            {

               break;
            }
           case 71:
            {

               break;
            }
           case 72:
            {

               break;
            }
           case 73:
            {

               break;
            }
           case 74:
            {

               break;
            }
           case 75:
            {

               break;
            }
           case 76:
            {

               break;
            }
           case 77:
            {

               break;
            }
           case 78:
            {

               break;
            }
           case 79:
            {

               break;
            }
           case 80:
            {

               break;
            }
           case 81:
            {

               break;
            }
           case 82:
            {

               break;
            }
           case 83:
            {

               break;
            }
           case 84:
            {

               break;
            }
           default:
            {
               eStatus = MB_ENOREG;
               break;
            }
         }

         break;
      }
     case MB_REG_WRITE:
      {

         switch (usAddress)
         {
           case 0: //  Stop/Start
            {

               break;
            }
           case 1: // Dir
            {

               break;
            }
           case 2: //Status start/stop
            {

               break;
            }
           case 3: //Status Dir
            {

               break;
            }
           case 4: // RPM
            {

               break;
            }
           case 5: //
            {
               break;
            }
           case 6: //
            {

               break;
            }
           case 7: //
            {
               break;
            }
           case 8: // save
            {
               FlashP->Write(settings);
               break;
            }
           case 9:
            {

               break;
            }
           case 10: // start PWM
            {
               uint16_t temp = 0;
               temp = temp | (*(pucRegBuffer) << 8);
               temp = temp | *(pucRegBuffer+1);
               if((temp > 0) && (temp <= 1000)){
                CH1 = temp;
                settings.Channels[0].DIMChannel = temp;
               }
               break;
            }
           case 11:
            {
                uint16_t temp = 0;
               temp = temp | (*(pucRegBuffer) << 8);
               temp = temp | *(pucRegBuffer+1);
               if((temp > 0) && (temp <= 1000)){
                CH2 = temp;
                settings.Channels[1].DIMChannel = temp;
               }
               break;
            }
           case 12:
            {
               uint16_t temp = 0;
               temp = temp | (*(pucRegBuffer) << 8);
               temp = temp | *(pucRegBuffer+1);
               if((temp > 0) && (temp <= 1000)){
                CH3 = temp;
                settings.Channels[2].DIMChannel = temp;
               }
               break;
            }
           case 13:
            {
               uint16_t temp = 0;
               temp = temp | (*(pucRegBuffer) << 8);
               temp = temp | *(pucRegBuffer+1);
               if((temp > 0) && (temp <= 1000)){
                CH4 = temp;
                settings.Channels[3].DIMChannel = temp;
               }
               break;
            }
           case 14:
            {
               uint16_t temp = 0;
               temp = temp | (*(pucRegBuffer) << 8);
               temp = temp | *(pucRegBuffer+1);
               if((temp > 0) && (temp <= 1000)){
                CH5 = temp;
                settings.Channels[4].DIMChannel = temp;
               }
               break;
            }
           case 15:
            {
               uint16_t temp = 0;
               temp = temp | (*(pucRegBuffer) << 8);
               temp = temp | *(pucRegBuffer+1);
               if((temp > 0) && (temp <= 1000)){
                CH6 = temp;
                settings.Channels[5].DIMChannel = temp;
               }
               break;
            }
           case 16:
            {
               uint16_t temp = 0;
               temp = temp | (*(pucRegBuffer) << 8);
               temp = temp | *(pucRegBuffer+1);
               if((temp > 0) && (temp <= 1000)){
                CH7 = temp;
                settings.Channels[6].DIMChannel = temp;
               }
               break;
            }
           case 17:
            {
               uint16_t temp = 0;
               temp = temp | (*(pucRegBuffer) << 8);
               temp = temp | *(pucRegBuffer+1);
               if((temp > 0) && (temp <= 1000)){
                CH8 = temp;
                settings.Channels[7].DIMChannel = temp;
               }
               break;
            }
           case 18:
            {
               uint16_t temp = 0;
               temp = temp | (*(pucRegBuffer) << 8);
               temp = temp | *(pucRegBuffer+1);
               if((temp > 0) && (temp <= 1000)){
                CH9 = temp;
                settings.Channels[8].DIMChannel = temp;
               }
               break;
            }
           case 19:
            {
               uint16_t temp = 0;
               temp = temp | (*(pucRegBuffer) << 8);
               temp = temp | *(pucRegBuffer+1);
               if((temp > 0) && (temp <= 1000)){
                CH10 = temp;
                settings.Channels[9].DIMChannel = temp;
               }
               break;
            }
           case 20:
            {
               uint16_t temp = 0;
               temp = temp | (*(pucRegBuffer) << 8);
               temp = temp | *(pucRegBuffer+1);
               if((temp > 0) && (temp <= 1000)){
                CH11 = temp;
                settings.Channels[10].DIMChannel = temp;
               }
               break;
            }
           case 21:
            {
               uint16_t temp = 0;
               temp = temp | (*(pucRegBuffer) << 8);
               temp = temp | *(pucRegBuffer+1);
               if((temp > 0) && (temp <= 1000)){
                CH12 = temp;
                settings.Channels[11].DIMChannel = temp;
               }
               break;
            }
           case 22:
            {
               uint16_t temp = 0;
               temp = temp | (*(pucRegBuffer) << 8);
               temp = temp | *(pucRegBuffer+1);
               if((temp > 0) && (temp <= 1000)){
                CH13 = temp;
                settings.Channels[12].DIMChannel = temp;
               }
               break;
            }
           case 23:
            {
               uint16_t temp = 0;
               temp = temp | (*(pucRegBuffer) << 8);
               temp = temp | *(pucRegBuffer+1);
               if((temp > 0) && (temp <= 1000)){
                CH14 = temp;
                settings.Channels[13].DIMChannel = temp;
               }
               break;
            }
           case 24:
            {
               uint16_t temp = 0;
               temp = temp | (*(pucRegBuffer) << 8);
               temp = temp | *(pucRegBuffer+1);
               if((temp > 0) && (temp <= 1000)){
                CH15 = temp;
                settings.Channels[14].DIMChannel = temp;
               }
               break;
            }
           case 25:
            {
               uint16_t temp = 0;
               temp = temp | (*(pucRegBuffer) << 8);
               temp = temp | *(pucRegBuffer+1);
               if((temp > 0) && (temp <= 1000)){
                CH16 = temp;
                settings.Channels[15].DIMChannel = temp;
               }
               break;
            }
           case 26:
            {
               uint16_t temp = 0;
               temp = temp | (*(pucRegBuffer) << 8);
               temp = temp | *(pucRegBuffer+1);
               if((temp > 0) && (temp <= 1000)){
                CH17 = temp;
                settings.Channels[16].DIMChannel = temp;
               }
               break;
            }
           case 27:
            {
               uint16_t temp = 0;
               temp = temp | (*(pucRegBuffer) << 8);
               temp = temp | *(pucRegBuffer+1);
               if((temp > 0) && (temp <= 1000)){
                CH18 = temp;
                settings.Channels[17].DIMChannel = temp;
               }
               break;
            }
           case 28:
            {
               uint16_t temp = 0;
               temp = temp | (*(pucRegBuffer) << 8);
               temp = temp | *(pucRegBuffer+1);
               if((temp > 0) && (temp <= 1000)){
                CH19 = temp;
                settings.Channels[18].DIMChannel = temp;
               }
               break;
            }
           case 29:
            {
               uint16_t temp = 0;
               temp = temp | (*(pucRegBuffer) << 8);
               temp = temp | *(pucRegBuffer+1);
               if((temp > 0) && (temp <= 1000)){
                CH20 = temp;
                settings.Channels[19].DIMChannel = temp;
               }
               break;
            }
           case 30:
            {
               uint16_t temp = 0;
               temp = temp | (*(pucRegBuffer) << 8);
               temp = temp | *(pucRegBuffer+1);
               if((temp > 0) && (temp <= 1000)){
                CH21 = temp;
                settings.Channels[20].DIMChannel = temp;
               }
               break;
            }
           case 31:
            {
               uint16_t temp = 0;
               temp = temp | (*(pucRegBuffer) << 8);
               temp = temp | *(pucRegBuffer+1);
               if((temp > 0) && (temp <= 1000)){
                CH22 = temp;
                settings.Channels[21].DIMChannel = temp;
               }
               break;
            }
           case 32:
            {
               uint16_t temp = 0;
               temp = temp | (*(pucRegBuffer) << 8);
               temp = temp | *(pucRegBuffer+1);
               if((temp > 0) && (temp <= 1000)){
                CH23 = temp;
                settings.Channels[22].DIMChannel = temp;
               }
               break;
            }
           case 33:
            {
               uint16_t temp = 0;
               temp = temp | (*(pucRegBuffer) << 8);
               temp = temp | *(pucRegBuffer+1);
               if((temp > 0) && (temp <= 1000)){
                CH24 = temp;
                settings.Channels[23].DIMChannel = temp;
                settings.Channels[24].DIMChannel = temp;
               }
               break;
            }
           case 34:
            {
               uint16_t temp = 0;
               temp = temp | (*(pucRegBuffer) << 8);
               temp = temp | *(pucRegBuffer+1);
               if((temp > 0) && (temp <= 1000)){
                CH24 = temp;
                settings.Channels[23].DIMChannel = temp;
                settings.Channels[24].DIMChannel = temp;
               }
               break;
            }
           case 35: // start enable
            {
               if(!*(pucRegBuffer+1)){
                  data_for_hc595 |= (uint32_t)(1 << 31);
               }else{
                  data_for_hc595 &= ~(1 << 31);
               }
               break;
            }
           case 36:
            {
               if(!*(pucRegBuffer+1)){
                  data_for_hc595 |= (uint32_t)(1 << 30);
               }else{
                  data_for_hc595 &= ~(1 << 30);
               }
               break;
            }
           case 37:
            {
               if(!*(pucRegBuffer+1)){
                  data_for_hc595 |= (uint32_t)(1 << 29);
               }else{
                  data_for_hc595 &= ~(1 << 29);
               }
               break;
            }
           case 38:
            {
               if(!*(pucRegBuffer+1)){
                  data_for_hc595 |= (uint32_t)(1 << 28);
               }else{
                  data_for_hc595 &= ~(1 << 28);
               }
               break;
            }
           case 39:
            {
               if(!*(pucRegBuffer+1)){
                  data_for_hc595 |= (uint32_t)(1 << 27);
               }else{
                  data_for_hc595 &= ~(1 << 27);
               }
               break;
            }
           case 40:
            {
               if(!*(pucRegBuffer+1)){
                  data_for_hc595 |= (uint32_t)(1 << 26);
               }else{
                  data_for_hc595 &= ~(1 << 26);
               }
               break;
            }
           case 41:
            {
               if(!*(pucRegBuffer+1)){
                  data_for_hc595 |= (uint32_t)(1 << 25);
               }else{
                  data_for_hc595 &= ~(1 << 25);
               }
               break;
            }
           case 42:
            {
               if(!*(pucRegBuffer+1)){
                  data_for_hc595 |= (uint32_t)(1 << 24);
               }else{
                  data_for_hc595 &= ~(1 << 24);
               }
               break;
            }
           case 43:
            {
               if(!*(pucRegBuffer+1)){
                  data_for_hc595 |= (uint32_t)(1 << 23);
               }else{
                  data_for_hc595 &= ~(1 << 23);
               }
               break;
            }
           case 44:
            {
               if(!*(pucRegBuffer+1)){
                  data_for_hc595 |= (uint32_t)(1 << 22);
               }else{
                  data_for_hc595 &= ~(1 << 22);
               }
               break;
            }
           case 45:
            {
               if(!*(pucRegBuffer+1)){
                  data_for_hc595 |= (uint32_t)(1 << 21);
               }else{
                  data_for_hc595 &= ~(1 << 21);
               }
               break;
            }
           case 46:
            {
               if(!*(pucRegBuffer+1)){
                  data_for_hc595 |= (uint32_t)(1 << 20);
               }else{
                  data_for_hc595 &= ~(1 << 20);
               }
               break;
            }
           case 47:
            {
               if(!*(pucRegBuffer+1)){
                  data_for_hc595 |= (uint32_t)(1 << 19);
               }else{
                  data_for_hc595 &= ~(1 << 19);
               }
               break;
            }
           case 48:
            {
               if(!*(pucRegBuffer+1)){
                  data_for_hc595 |= (uint32_t)(1 << 18);
               }else{
                  data_for_hc595 &= ~(1 << 18);
               }
               break;
            }
           case 49:
            {
               if(!*(pucRegBuffer+1)){
                  data_for_hc595 |= (uint32_t)(1 << 17);
               }else{
                  data_for_hc595 &= ~(1 << 17);
               }
               break;
            }
           case 50:
            {
               if(!*(pucRegBuffer+1)){
                  data_for_hc595 |= (uint32_t)(1 << 16);
               }else{
                  data_for_hc595 &= ~(1 << 16);
               }
               break;
            }
           case 51:
            {
               if(!*(pucRegBuffer+1)){
                  data_for_hc595 |= (uint32_t)(1 << 15);
               }else{
                  data_for_hc595 &= ~(1 << 15);
               }
               break;
            }
           case 52:
            {
               if(!*(pucRegBuffer+1)){
                  data_for_hc595 |= (uint32_t)(1 << 14);
               }else{
                  data_for_hc595 &= ~(1 << 14);
               }
               break;
            }
           case 53:
            {
               if(!*(pucRegBuffer+1)){
                  data_for_hc595 |= (uint32_t)(1 << 13);
               }else{
                  data_for_hc595 &= ~(1 << 13);
               }
               break;
            }
           case 54:
            {
               if(!*(pucRegBuffer+1)){
                  data_for_hc595 |= (uint32_t)(1 << 12);
               }else{
                  data_for_hc595 &= ~(1 << 12);
               }
               break;
            }
           case 55:
            {
               if(!*(pucRegBuffer+1)){
                  data_for_hc595 |= (uint32_t)(1 << 11);
               }else{
                  data_for_hc595 &= ~(1 << 11);
               }
               break;
            }
           case 56:
            {
               if(!*(pucRegBuffer+1)){
                  data_for_hc595 |= (uint32_t)(1 << 10);
               }else{
                  data_for_hc595 &= ~(1 << 10);
               }
               break;
            }
           case 57:
            {
               if(!*(pucRegBuffer+1)){
                  data_for_hc595 |= (uint32_t)(1 << 9);
               }else{
                  data_for_hc595 &= ~(1 << 9);
               }
               break;
            }
           case 58:
            {
               if(!*(pucRegBuffer+1)){
                  data_for_hc595 |= (uint32_t)(1 << 8);
               }else{
                  data_for_hc595 &= ~(1 << 8);
               }
               break;
            }
           case 59:
            {
               if(!*(pucRegBuffer+1)){
                  data_for_hc595 |= (uint32_t)(1 << 7);
               }else{
                  data_for_hc595 &= ~(1 << 7);
               }
               break;
            }
           case 60: // chanels is down
            {	//V=ADCval*VALmax/ADCmax. 4095

               //*pucRegBuffer = ((UCHAR*) &CH1_CH10[0])+1;
               //*pucRegBuffer +1 = ((UCHAR*) &CH1_CH10[0]);
               break;
            }
           case 61:
            {

               break;
            }
           case 62:
            {

               break;
            }
           case 63:
            {

               break;
            }
           case 64:
            {

               break;
            }
           case 65:
            {

               break;
            }
           case 66:
            {

               break;
            }
           case 67:
            {

               break;
            }
           case 68:
            {

               break;
            }
           case 69:
            {

               break;
            }
           case 70:
            {

               break;
            }
           case 71:
            {

               break;
            }
           case 72:
            {

               break;
            }
           case 73:
            {

               break;
            }
           case 74:
            {

               break;
            }
           case 75:
            {

               break;
            }
           case 76:
            {

               break;
            }
           case 77:
            {

               break;
            }
           case 78:
            {

               break;
            }
           case 79:
            {

               break;
            }
           case 80:
            {

               break;
            }
           case 81:
            {

               break;
            }
           case 82:
            {

               break;
            }
           case 83:
            {

               break;
            }
           case 84:
            {

               break;
            }
           default:
            {
               eStatus = MB_ENOREG;
               break;
            }
         }
         break;
      }
     default:
      {
         eStatus = MB_EINVAL;
         break;
      }
   }

   return eStatus;
}

// 0x01 0x0f 0x05
eMBErrorCode
eMBRegCoilsCB( UCHAR * pucRegBuffer, USHORT usAddress, USHORT usNCoils, eMBRegisterMode eMode )
{
   return MB_ENOREG;
}
//0x02
eMBErrorCode
eMBRegDiscreteCB( UCHAR * pucRegBuffer, USHORT usAddress, USHORT usNDiscrete )
{
   return MB_ENOREG;
}
/* USER CODE END Application */
